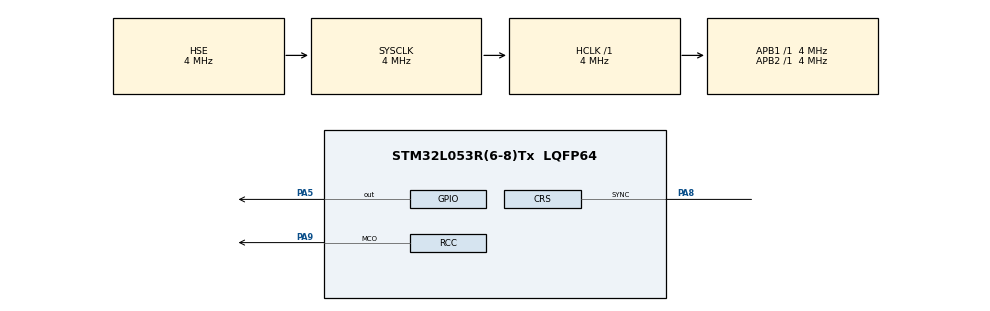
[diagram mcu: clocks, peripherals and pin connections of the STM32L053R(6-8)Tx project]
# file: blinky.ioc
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Mcu.Family=STM32L0
Mcu.Name=STM32L053R(6-8)Tx
Mcu.Package=LQFP64
PA5.Signal=GPIO_Output
PA8.Mode=CRS SYNC Source GPIO
PA8.Signal=CRS_SYNC
PA9.Mode=Clock-out
PA9.Signal=RCC_MCO
PC14-OSC32_IN.Mode=LSE-External-Oscillator
PC14-OSC32_IN.Signal=RCC_OSC32_IN
PC15-OSC32_OUT.Mode=LSE-External-Oscillator
PC15-OSC32_OUT.Signal=RCC_OSC32_OUT
PH0-OSC_IN.Mode=HSE-External-Oscillator
PH0-OSC_IN.Signal=RCC_OSC_IN
PH1-OSC_OUT.Mode=HSE-External-Oscillator
PH1-OSC_OUT.Signal=RCC_OSC_OUT
ProjectManager.HeapSize=0x200
ProjectManager.StackSize=0x400
ProjectManager.TargetToolchain=STM32CubeIDE
RCC.AHBFreq_Value=4000000
RCC.APB1Freq_Value=4000000
RCC.APB1TimFreq_Value=4000000
RCC.APB2Freq_Value=4000000
RCC.APB2TimFreq_Value=4000000
RCC.HCLKFreq_Value=4000000
RCC.HSE_VALUE=4000000
RCC.HSI16_VALUE=16000000
RCC.HSI48_VALUE=48000000
RCC.HSI_VALUE=16000000
RCC.MSI_VALUE=2097000
RCC.PLLMUL=RCC_PLLMUL_4
RCC.PLLSourceVirtual=RCC_PLLSOURCE_HSE
RCC.RCC_MCOSource=RCC_MCO1SOURCE_HSE
RCC.SYSCLKFreq_VALUE=4000000
RCC.SYSCLKSource=RCC_SYSCLKSOURCE_HSE
RCC.VCOOutputFreq_Value=16000000
board=custom

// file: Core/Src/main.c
/* USER CODE BEGIN Header */
/**
  ******************************************************************************
  * @file           : main.c
  * @brief          : Main program body
  ******************************************************************************
  * @attention
  *
  * Copyright (c) 2025 STMicroelectronics.
  * All rights reserved.
  *
  * This software is licensed under terms that can be found in the LICENSE file
  * in the root directory of this software component.
  * If no LICENSE file comes with this software, it is provided AS-IS.
  *
  ******************************************************************************
  */
/* USER CODE END Header */
#include "main.h"

void SystemClock_Config(void);
static void MX_GPIO_Init(void);

int main(void)
{

  /* USER CODE BEGIN 1 */
	uint32_t tick_ms = 0;
  /* USER CODE END 1 */

  /* MCU Configuration--------------------------------------------------------*/

  /* Reset of all peripherals, Initializes the Flash interface and the Systick. */
  HAL_Init();

  /* Configure the system clock */
  SystemClock_Config();

  /* Initialize all configured peripherals */
  MX_GPIO_Init();
  /* USER CODE BEGIN 2 */
  uint16_t flag = 0;
  /* USER CODE END 2 */

  /* Infinite loop */
  /* USER CODE BEGIN WHILE */
  tick_ms = HAL_GetTick();
  while (1)
  {
	  if (HAL_GetTick() - tick_ms > 500	){
		  //500 ms elapsed
		  tick_ms = HAL_GetTick();
		 /*if (flag == 0) {
			  HAL_GPIO_WritePin(GPIOA, GPIO_PIN_5, GPIO_PIN_SET);
			  flag = 1;
		  }
		  else{
			  HAL_GPIO_WritePin(GPIOA, GPIO_PIN_5, GPIO_PIN_RESET);
			  flag = 0;
		  }*/
		  HAL_GPIO_TogglePin(GPIOA, GPIO_PIN_5);

	  }
    /* USER CODE END WHILE */

  }
}

void SystemClock_Config(void)
{
  RCC_OscInitTypeDef RCC_OscInitStruct = {0};
  RCC_ClkInitTypeDef RCC_ClkInitStruct = {0};
  RCC_CRSInitTypeDef RCC_CRSInitStruct = {0};

  /** Configure the main internal regulator output voltage
  */
  __HAL_PWR_VOLTAGESCALING_CONFIG(PWR_REGULATOR_VOLTAGE_SCALE1);

  /** Initializes the RCC Oscillators according to the specified parameters
  * in the RCC_OscInitTypeDef structure.
  */
  RCC_OscInitStruct.OscillatorType = RCC_OSCILLATORTYPE_HSE;
  RCC_OscInitStruct.HSEState = RCC_HSE_ON;
  RCC_OscInitStruct.PLL.PLLState = RCC_PLL_NONE;
  if (HAL_RCC_OscConfig(&RCC_OscInitStruct) != HAL_OK)
  {
    Error_Handler();
  }

  /** Initializes the CPU, AHB and APB buses clocks
  */
  RCC_ClkInitStruct.ClockType = RCC_CLOCKTYPE_HCLK|RCC_CLOCKTYPE_SYSCLK
                              |RCC_CLOCKTYPE_PCLK1|RCC_CLOCKTYPE_PCLK2;
  RCC_ClkInitStruct.SYSCLKSource = RCC_SYSCLKSOURCE_HSE;
  RCC_ClkInitStruct.AHBCLKDivider = RCC_SYSCLK_DIV1;
  RCC_ClkInitStruct.APB1CLKDivider = RCC_HCLK_DIV1;
  RCC_ClkInitStruct.APB2CLKDivider = RCC_HCLK_DIV1;

  if (HAL_RCC_ClockConfig(&RCC_ClkInitStruct, FLASH_LATENCY_0) != HAL_OK)
  {
    Error_Handler();
  }
  HAL_RCC_MCOConfig(RCC_MCO2, RCC_MCO1SOURCE_HSE, RCC_MCODIV_1);

  /** Enable the SYSCFG APB clock
  */
  __HAL_RCC_CRS_CLK_ENABLE();

  /** Configures CRS
  */
  RCC_CRSInitStruct.Prescaler = RCC_CRS_SYNC_DIV1;
  RCC_CRSInitStruct.Source = RCC_CRS_SYNC_SOURCE_GPIO;
  RCC_CRSInitStruct.Polarity = RCC_CRS_SYNC_POLARITY_RISING;
  RCC_CRSInitStruct.ReloadValue = __HAL_RCC_CRS_RELOADVALUE_CALCULATE(48000000,1);
  RCC_CRSInitStruct.ErrorLimitValue = 34;
  RCC_CRSInitStruct.HSI48CalibrationValue = 32;

  HAL_RCCEx_CRSConfig(&RCC_CRSInitStruct);
}

static void MX_GPIO_Init(void)
{
  GPIO_InitTypeDef GPIO_InitStruct = {0};

  /* GPIO Ports Clock Enable */
  __HAL_RCC_GPIOC_CLK_ENABLE();
  __HAL_RCC_GPIOH_CLK_ENABLE();
  __HAL_RCC_GPIOA_CLK_ENABLE();

  /*Configure GPIO pin Output Level */
  HAL_GPIO_WritePin(GPIOA, GPIO_PIN_5, GPIO_PIN_RESET);

  /*Configure GPIO pin : PA5 */
  GPIO_InitStruct.Pin = GPIO_PIN_5;
  GPIO_InitStruct.Mode = GPIO_MODE_OUTPUT_PP;
  GPIO_InitStruct.Pull = GPIO_NOPULL;
  GPIO_InitStruct.Speed = GPIO_SPEED_FREQ_LOW;
  HAL_GPIO_Init(GPIOA, &GPIO_InitStruct);

  /*Configure GPIO pin : PA8 */
  GPIO_InitStruct.Pin = GPIO_PIN_8;
  GPIO_InitStruct.Mode = GPIO_MODE_AF_PP;
  GPIO_InitStruct.Pull = GPIO_NOPULL;
  GPIO_InitStruct.Speed = GPIO_SPEED_FREQ_LOW;
  GPIO_InitStruct.Alternate = GPIO_AF2_USB;
  HAL_GPIO_Init(GPIOA, &GPIO_InitStruct);

  /*Configure GPIO pin : PA9 */
  GPIO_InitStruct.Pin = GPIO_PIN_9;
  GPIO_InitStruct.Mode = GPIO_MODE_AF_PP;
  GPIO_InitStruct.Pull = GPIO_NOPULL;
  GPIO_InitStruct.Speed = GPIO_SPEED_FREQ_LOW;
  GPIO_InitStruct.Alternate = GPIO_AF0_MCO;
  HAL_GPIO_Init(GPIOA, &GPIO_InitStruct);

}

void Error_Handler(void)
{
  __disable_irq();
  while (1)
  {
  }
}
